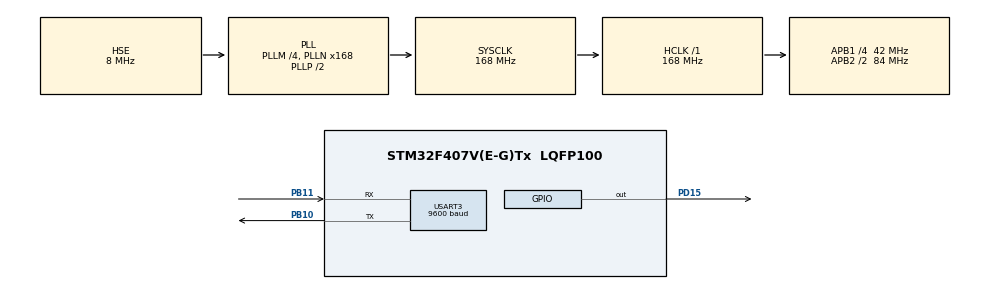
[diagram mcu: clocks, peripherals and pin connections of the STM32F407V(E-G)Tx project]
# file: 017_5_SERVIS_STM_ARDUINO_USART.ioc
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Mcu.Family=STM32F4
RCC.PLLSourceVirtual=RCC_PLLSOURCE_HSE
PH0-OSC_IN.Signal=RCC_OSC_IN
RCC.CortexFreq_Value=168000000
PB10.Mode=Asynchronous
RCC.APB1CLKDivider=RCC_HCLK_DIV4
PB11.Signal=USART3_RX
RCC.SYSCLKSource=RCC_SYSCLKSOURCE_PLLCLK
ProjectManager.StackSize=0x400
PA13.Signal=SYS_JTMS-SWDIO
USART3.BaudRate=9600
PB11.Mode=Asynchronous
ProjectManager.TargetToolchain=STM32CubeIDE
RCC.HCLKFreq_Value=168000000
RCC.APB2TimFreq_Value=168000000
RCC.LSE_VALUE=32768
RCC.AHBFreq_Value=168000000
PH0-OSC_IN.Mode=HSE-External-Oscillator
PB10.Signal=USART3_TX
RCC.HSE_VALUE=8000000
board=custom
RCC.VCOOutputFreq_Value=336000000
RCC.APB2Freq_Value=84000000
PA14.Mode=Serial_Wire
PH1-OSC_OUT.Signal=RCC_OSC_OUT
PA13.Mode=Serial_Wire
Mcu.Name=STM32F407V(E-G)Tx
PH1-OSC_OUT.Mode=HSE-External-Oscillator
RCC.48MHZClocksFreq_Value=84000000
RCC.SYSCLKFreq_VALUE=168000000
Mcu.Package=LQFP100
USART3.VirtualMode=VM_ASYNC
PA14.Signal=SYS_JTCK-SWCLK
ProjectManager.HeapSize=0x200
RCC.HSI_VALUE=16000000
NVIC.PriorityGroup=NVIC_PRIORITYGROUP_4
RCC.APB2CLKDivider=RCC_HCLK_DIV2
RCC.PLLM=4
RCC.PLLN=168
RCC.APB1TimFreq_Value=84000000
RCC.APB1Freq_Value=42000000
PD15.Signal=GPIO_Output

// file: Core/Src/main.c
/* USER CODE BEGIN Header */
/**
  ******************************************************************************
  * @file           : main.c
  * @brief          : Main program body
  ******************************************************************************
  * @attention
  *
  * <h2><center>&copy; Copyright (c) 2021 STMicroelectronics.
  * All rights reserved.</center></h2>
  *
  * This software component is licensed by ST under BSD 3-Clause license,
  * the "License"; You may not use this file except in compliance with the
  * License. You may obtain a copy of the License at:
  *                        opensource.org/licenses/BSD-3-Clause
  *
  ******************************************************************************
  */
/* USER CODE END Header */
#include "main.h"

/* USER CODE BEGIN Includes */

#include "string.h"

/* USER CODE END Includes */

UART_HandleTypeDef huart3;

/* USER CODE BEGIN PV */

//int n[10] = { 32, 27, 64, 18, 95, 14, 90, 70, 60, 37 };

int dizi[] = {1,2,3,4,5};

/* USER CODE END PV */

void SystemClock_Config(void);
static void MX_GPIO_Init(void);
static void MX_USART3_UART_Init(void);

int main(void)
{

  /* MCU Configuration--------------------------------------------------------*/

  /* Reset of all peripherals, Initializes the Flash interface and the Systick. */
  HAL_Init();

  /* Configure the system clock */
  SystemClock_Config();

  /* Initialize all configured peripherals */
  MX_GPIO_Init();
  MX_USART3_UART_Init();

  /* Infinite loop */
  while (1)
  {

    /* USER CODE BEGIN 3 */
//	  str = "123456";
	  HAL_UART_Transmit(&huart3, (uint8_t*)dizi, 5, HAL_MAX_DELAY);
	  HAL_Delay(1000);

  }
  /* USER CODE END 3 */
}

void SystemClock_Config(void)
{
  RCC_OscInitTypeDef RCC_OscInitStruct = {0};
  RCC_ClkInitTypeDef RCC_ClkInitStruct = {0};

  /** Configure the main internal regulator output voltage
  */
  __HAL_RCC_PWR_CLK_ENABLE();
  __HAL_PWR_VOLTAGESCALING_CONFIG(PWR_REGULATOR_VOLTAGE_SCALE1);
  /** Initializes the RCC Oscillators according to the specified parameters
  * in the RCC_OscInitTypeDef structure.
  */
  RCC_OscInitStruct.OscillatorType = RCC_OSCILLATORTYPE_HSE;
  RCC_OscInitStruct.HSEState = RCC_HSE_ON;
  RCC_OscInitStruct.PLL.PLLState = RCC_PLL_ON;
  RCC_OscInitStruct.PLL.PLLSource = RCC_PLLSOURCE_HSE;
  RCC_OscInitStruct.PLL.PLLM = 4;
  RCC_OscInitStruct.PLL.PLLN = 168;
  RCC_OscInitStruct.PLL.PLLP = RCC_PLLP_DIV2;
  RCC_OscInitStruct.PLL.PLLQ = 4;
  if (HAL_RCC_OscConfig(&RCC_OscInitStruct) != HAL_OK)
  {
    Error_Handler();
  }
  /** Initializes the CPU, AHB and APB buses clocks
  */
  RCC_ClkInitStruct.ClockType = RCC_CLOCKTYPE_HCLK|RCC_CLOCKTYPE_SYSCLK
                              |RCC_CLOCKTYPE_PCLK1|RCC_CLOCKTYPE_PCLK2;
  RCC_ClkInitStruct.SYSCLKSource = RCC_SYSCLKSOURCE_PLLCLK;
  RCC_ClkInitStruct.AHBCLKDivider = RCC_SYSCLK_DIV1;
  RCC_ClkInitStruct.APB1CLKDivider = RCC_HCLK_DIV4;
  RCC_ClkInitStruct.APB2CLKDivider = RCC_HCLK_DIV2;

  if (HAL_RCC_ClockConfig(&RCC_ClkInitStruct, FLASH_LATENCY_5) != HAL_OK)
  {
    Error_Handler();
  }
}

static void MX_USART3_UART_Init(void)
{

  huart3.Instance = USART3;
  huart3.Init.BaudRate = 9600;
  huart3.Init.WordLength = UART_WORDLENGTH_8B;
  huart3.Init.StopBits = UART_STOPBITS_1;
  huart3.Init.Parity = UART_PARITY_NONE;
  huart3.Init.Mode = UART_MODE_TX_RX;
  huart3.Init.HwFlowCtl = UART_HWCONTROL_NONE;
  huart3.Init.OverSampling = UART_OVERSAMPLING_16;
  if (HAL_UART_Init(&huart3) != HAL_OK)
  {
    Error_Handler();
  }

}

static void MX_GPIO_Init(void)
{
  GPIO_InitTypeDef GPIO_InitStruct = {0};

  /* GPIO Ports Clock Enable */
  __HAL_RCC_GPIOH_CLK_ENABLE();
  __HAL_RCC_GPIOB_CLK_ENABLE();
  __HAL_RCC_GPIOD_CLK_ENABLE();
  __HAL_RCC_GPIOA_CLK_ENABLE();

  /*Configure GPIO pin Output Level */
  HAL_GPIO_WritePin(GPIOD, GPIO_PIN_15, GPIO_PIN_RESET);

  /*Configure GPIO pin : PD15 */
  GPIO_InitStruct.Pin = GPIO_PIN_15;
  GPIO_InitStruct.Mode = GPIO_MODE_OUTPUT_PP;
  GPIO_InitStruct.Pull = GPIO_NOPULL;
  GPIO_InitStruct.Speed = GPIO_SPEED_FREQ_LOW;
  HAL_GPIO_Init(GPIOD, &GPIO_InitStruct);

}

void Error_Handler(void)
{
  __disable_irq();
  while (1)
  {
  }
}

/************************ (C) COPYRIGHT STMicroelectronics *****END OF FILE****/
